# nrf52 register map
Vendor: Nordic Semiconductor; Series: nrf52; File version: 1
CPU: CM4 r0p1, little endian, MPU, FPU, 3 interrupt priority bits
Registers are 32-bit, read-write, reset 0x0 unless marked. A register's access mark holds for its fields unless they carry their own. Offsets are from the block's base; [hi:lo] are bit positions; lines under a group give offsets from that group; {n}, {i} and the like mark numbered series; 'fields as' and 'values as' point back to an identical list.

## SWI0 — Software interrupt 0
Base 0x40014000
Same registers: SWI1 0x40015000, SWI2 0x40016000, SWI3 0x40017000, SWI4 0x40018000, SWI5 0x40019000

## EGU0 — Event Generator Unit 0
Base 0x40014000; alternate view of SWI0
Same registers: EGU1 0x40015000 (alternate view of SWI1), EGU2 0x40016000 (alternate view of SWI2), EGU3 0x40017000 (alternate view of SWI3), EGU4 0x40018000 (alternate view of SWI4), EGU5 0x40019000 (alternate view of SWI5)
{0x0+4i} TASKS_TRIGGER[{i}] (i=0..15) wo — Description collection[0]: Trigger 0 for triggering the corresponding TRIGGERED[0] event
{0x100+4i} EVENTS_TRIGGERED[{i}] (i=0..15) — Description collection[0]: Event number 0 generated by triggering the corresponding TRIGGER[0] task
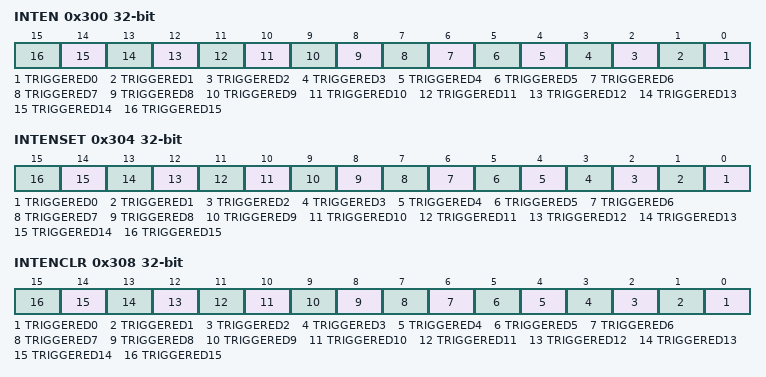
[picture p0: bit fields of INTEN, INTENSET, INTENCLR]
0x300 INTEN — Enable or disable interrupt
  [all] fields
    0=Disabled; 1=Enabled
  [n] TRIGGERED{n} (n=0..15) — Enable or disable interrupt for TRIGGERED[{n}] event
0x304 INTENSET — Enable interrupt
  [all] fields
    on read: 0=Disabled (Read: Disabled); 1=Enabled (Read: Enabled) | on write: 1=Set (Enable)
  [n] TRIGGERED{n} (n=0..15) — Write '1' to Enable interrupt for TRIGGERED[{n}] event
0x308 INTENCLR — Disable interrupt
  [all] fields
    on read: 0=Disabled (Read: Disabled); 1=Enabled (Read: Enabled) | on write: 1=Clear (Disable)
  [n] TRIGGERED{n} (n=0..15) — Write '1' to Disable interrupt for TRIGGERED[{n}] event

## TIMER3 — Timer/Counter 3
Base 0x4001A000
Same registers: TIMER4 0x4001B000
0x00 TASKS_START wo — Start Timer
0x04 TASKS_STOP wo — Stop Timer
0x08 TASKS_COUNT wo — Increment Timer (Counter mode only)
0x0C TASKS_CLEAR wo — Clear time
0x10 TASKS_SHUTDOWN wo — Deprecated register - Shut down timer
{0x40+4i} TASKS_CAPTURE[{i}] (i=0..5) wo — Description collection[0]: Capture Timer value to CC[0] register
{0x140+4i} EVENTS_COMPARE[{i}] (i=0..5) — Description collection[0]: Compare event on CC[0] match
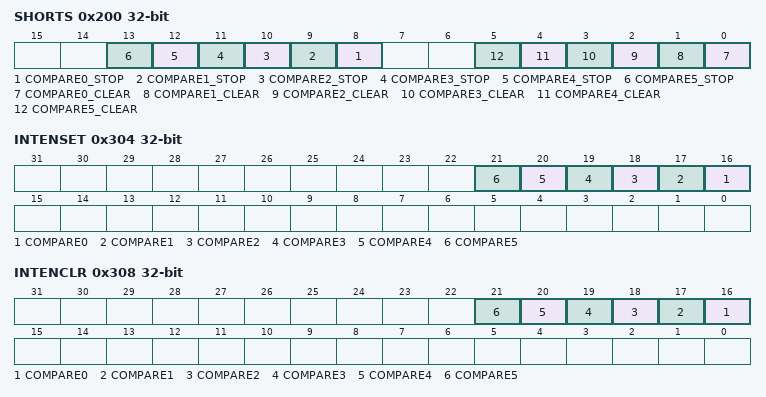
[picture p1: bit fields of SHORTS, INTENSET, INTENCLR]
0x200 SHORTS — Shortcut register
  [all] fields
    0=Disabled (Disable shortcut); 1=Enabled (Enable shortcut)
  [n+8] COMPARE{n}_STOP (n=0..5) — Shortcut between COMPARE[{n}] event and STOP task
  [n] COMPARE{n}_CLEAR (n=0..5) — Shortcut between COMPARE[{n}] event and CLEAR task
0x304 INTENSET — Enable interrupt
  [all] fields
    on read: 0=Disabled (Read: Disabled); 1=Enabled (Read: Enabled) | on write: 1=Set (Enable)
  [n+16] COMPARE{n} (n=0..5) — Write '1' to Enable interrupt for COMPARE[{n}] event
0x308 INTENCLR — Disable interrupt
  [all] fields
    on read: 0=Disabled (Read: Disabled); 1=Enabled (Read: Enabled) | on write: 1=Clear (Disable)
  [n+16] COMPARE{n} (n=0..5) — Write '1' to Disable interrupt for COMPARE[{n}] event
0x504 MODE — Timer mode selection
  [1:0] MODE — Timer mode
    0=Timer (Select Timer mode); 1=Counter (Deprecated enumerator - Select Counter mode); 2=LowPowerCounter (Select Low Power Counter mode)
0x508 BITMODE — Configure the number of bits used by the TIMER
  [1:0] BITMODE — Timer bit width
    0=16 bit timer bit width; 1=08Bit (8 bit timer bit width); 2=24 bit timer bit width; 3=32 bit timer bit width
0x510 PRESCALER reset 0x4 — Timer prescaler register
  [3:0] PRESCALER — Prescaler value
{0x540+4i} CC[{i}] (i=0..5) — Description collection[0]: Capture/Compare register 0
  [31:0] CC — Capture/Compare value

## PDM — Pulse Density Modulation (Digital Microphone) Interface
Base 0x4001D000
0x00 TASKS_START wo — Starts continuous PDM transfer
0x04 TASKS_STOP wo — Stops PDM transfer
0x100 EVENTS_STARTED — PDM transfer has started
0x104 EVENTS_STOPPED — PDM transfer has finished
0x108 EVENTS_END — The PDM has written the last sample specified by SAMPLE.MAXCNT (or the last sample after a STOP task has been received) to Data RAM
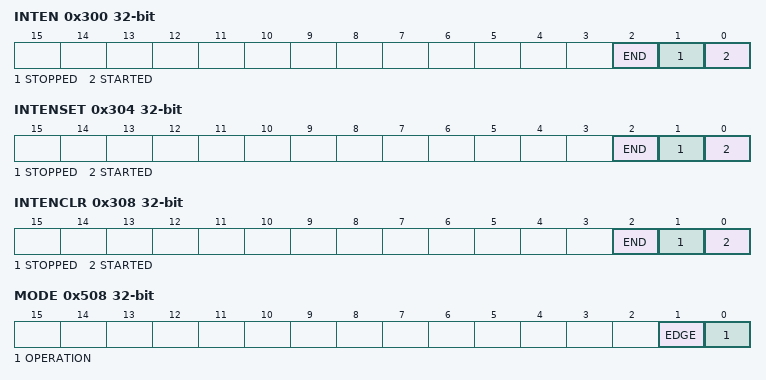
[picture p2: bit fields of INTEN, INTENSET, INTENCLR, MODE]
0x300 INTEN — Enable or disable interrupt
  [all] fields
    0=Disabled; 1=Enabled
  [2] END — Enable or disable interrupt for END event
  [1] STOPPED — Enable or disable interrupt for STOPPED event
  [0] STARTED — Enable or disable interrupt for STARTED event
0x304 INTENSET — Enable interrupt
  [all] fields
    on read: 0=Disabled (Read: Disabled); 1=Enabled (Read: Enabled) | on write: 1=Set (Enable)
  [2] END — Write '1' to Enable interrupt for END event
  [1] STOPPED — Write '1' to Enable interrupt for STOPPED event
  [0] STARTED — Write '1' to Enable interrupt for STARTED event
0x308 INTENCLR — Disable interrupt
  [all] fields
    on read: 0=Disabled (Read: Disabled); 1=Enabled (Read: Enabled) | on write: 1=Clear (Disable)
  [2] END — Write '1' to Disable interrupt for END event
  [1] STOPPED — Write '1' to Disable interrupt for STOPPED event
  [0] STARTED — Write '1' to Disable interrupt for STARTED event
0x500 ENABLE — PDM module enable register
  [0] ENABLE — Enable or disable PDM module
    0=Disabled; 1=Enabled
0x504 PDMCLKCTRL reset 0x8400000 — PDM clock generator control
  [31:0] FREQ — PDM_CLK frequency
    0x8000000=1000K (PDM_CLK = 32 MHz / 32 = 1.000 MHz); 0x8400000=Default (PDM_CLK = 32 MHz / 31 = 1.032 MHz); 0x8800000=1067K (PDM_CLK = 32 MHz / 30 = 1.067 MHz)
0x508 MODE — Defines the routing of the connected PDM microphones' signals
  [1] EDGE — Defines on which PDM_CLK edge Left (or mono) is sampled
    0=LeftFalling (Left (or mono) is sampled on falling edge of PDM_CLK); 1=LeftRising (Left (or mono) is sampled on rising edge of PDM_CLK)
  [0] OPERATION — Mono or stereo operation
    0=Stereo (Sample and store one pair (Left + Right) of 16bit samples per RAM word R=[31:16]; L=[15:0]); 1=Mono (Sample and store two successive Left samples (16 bit each) per RAM word L1=[31:16]; L0=[15:0])
0x518 GAINL reset 0x28 — Left output gain adjustment
  [6:0] GAINL — Left output gain adjustment, in 0.5 dB steps, around the default module gain (see electrical parameters) 0x00 -20 dB gain adjust 0x01 -19.5 dB gain adjust (...) 0x27 -0.5 dB gain adjust 0x28 0 dB gain adjust 0x29 +0.5 dB gain adjust (...) 0x4F +19.5 dB gain adjust 0x50 +20 dB gain adjust
    0=MinGain (-20dB gain adjustment (minimum)); 40=DefaultGain (0dB gain adjustment ('2500 RMS' requirement)); 80=MaxGain (+20dB gain adjustment (maximum))
0x51C GAINR reset 0x28 — Right output gain adjustment
  [7:0] GAINR — Right output gain adjustment, in 0.5 dB steps, around the default module gain (see electrical parameters)
    values as GAINL.GAINL
0x540 PSEL group — Unspecified
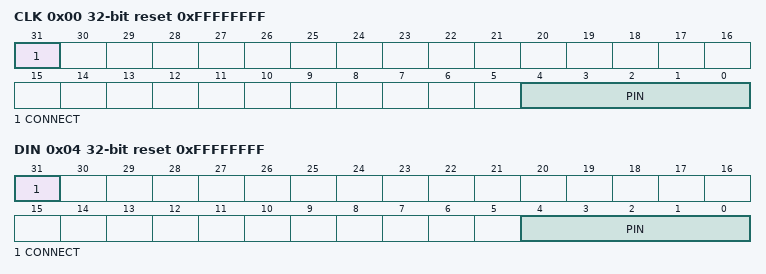
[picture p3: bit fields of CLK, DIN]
  0x00 CLK reset 0xFFFFFFFF — Pin number configuration for PDM CLK signal
    [31] CONNECT — Connection
      1=Disconnected; 0=Connected
    [4:0] PIN — Pin number
  0x04 DIN reset 0xFFFFFFFF — Pin number configuration for PDM DIN signal
    fields as PSEL.CLK
0x560 SAMPLE group — Unspecified
  0x00 PTR — RAM address pointer to write samples to with EasyDMA
    [31:0] SAMPLEPTR — Address to write PDM samples to over DMA
  0x04 MAXCNT — Number of samples to allocate memory for in EasyDMA mode
    [14:0] BUFFSIZE — Length of DMA RAM allocation in number of samples
